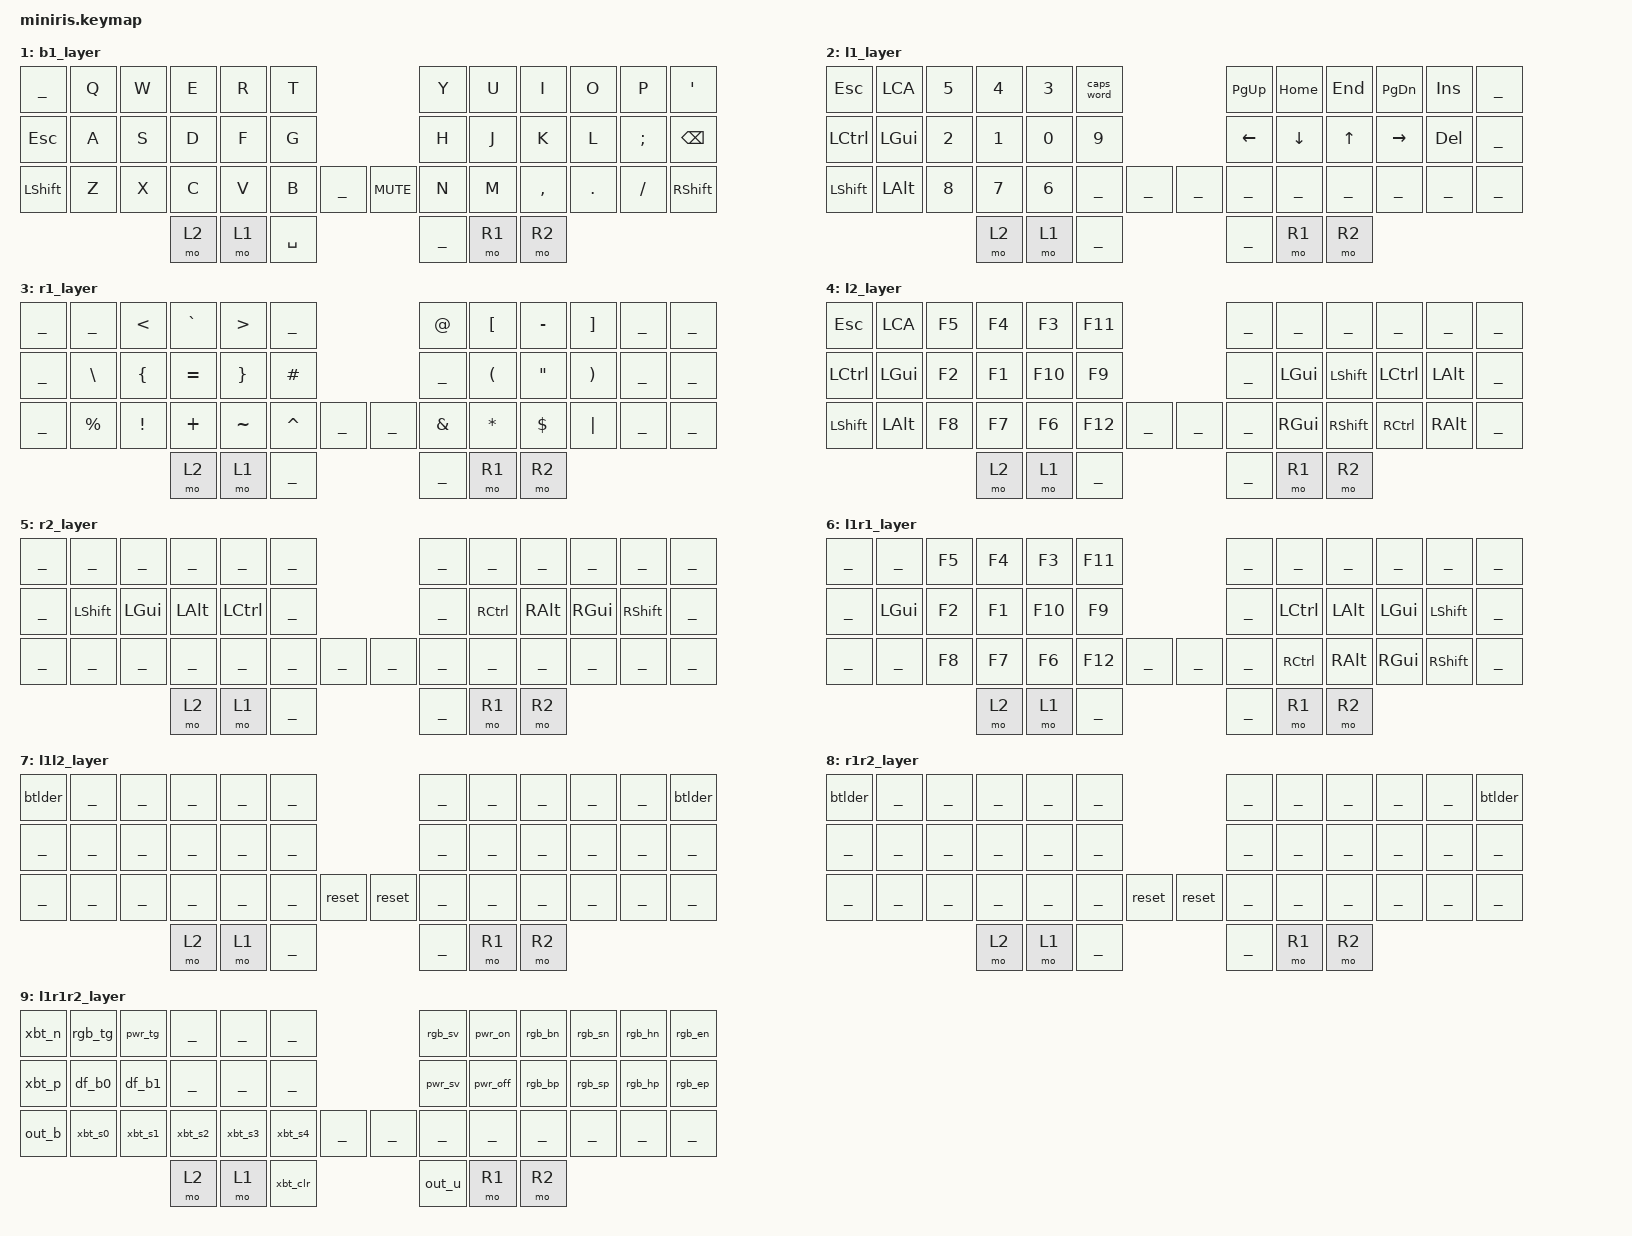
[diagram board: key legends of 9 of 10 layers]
#include <behaviors.dtsi>
#include <dt-bindings/zmk/keys.h>

#include "include/rgb_underglow.h"
#include "include/layers.dtsi"
#include "include/outputs.h"
#include "include/power.dtsi"
#include "include/power_rgb_underglow.dtsi"

#include "include/behaviors_ht.dtsi"
#include "include/miniris_homerow_mods.dtsi"
#include "include/keycodes.h"

/ {
keymap {
compatible = "zmk,keymap";
default_layer { bindings = <

  &kp TAB    &kp Q      &kp W      &kp E      LR1__ R    &kp T                         &kp Y      RR1__ U    &kp I      &kp O      &kp P      &kp SQT
  LC_ESC     LS__ A     LG__ S     LA__ D     LC__ F     LL1__ G                       RL1__ H    RC__ J     RA__ K     RG__ L     RS__ SEMI  RC_BSPC
  &kp LSHFT  &kp Z      &kp X      &kp C      LL1__ V    &kp B      ______ &kp C_MUTE  &kp N      RL1__ M    &kp COMMA  &kp DOT    &kp FSLH   &kp RSHFT
                                   &mo L2     &mo L1     &kp SPACE                     &kp RET    &mo R1     &mo R2                                         >;sensor-bindings = <
                                                                                                                                                            &inc_dec_kp N0 N1 &inc_dec_kp C_VOL_DN C_VOL_UP
                                                                                                                                                            >; };b1_layer { bindings = <
  ______     &kp Q      &kp W      &kp E      &kp R      &kp T                         &kp Y      &kp U      &kp I      &kp O      &kp P      &kp SQT
  &kp ESC    &kp A      &kp S      &kp D      &kp F      &kp G                         &kp H      &kp J      &kp K      &kp L      &kp SEMI   &kp BSPC
  &kp LSHFT  &kp Z      &kp X      &kp C      &kp V      &kp B      ______ &kp C_MUTE  &kp N      &kp M      &kp COMMA  &kp DOT    &kp FSLH   &kp RSHFT
                                   &mo L2     &mo L1     &kp SPACE                     ______     &mo R1     &mo R2                                         >;sensor-bindings = <
                                                                                                                                                            &inc_dec_kp N0 N1 &inc_dec_kp C_VOL_DN C_VOL_UP
                                                                                                                                                            >; };l1_layer { bindings = <
  &kp ESC    LCA        &kp N5     &kp N4     &kp N3     &caps_word                    &kp PG_UP  &kp HOME   &kp END    &kp PG_DN  &kp INS    ______
  &kp LCTRL  &kp LGUI   &kp N2     &kp N1     &kp N0     &kp N9                        &kp LEFT   &kp DOWN   &kp UP     &kp RIGHT  &kp DEL    ______
  &kp LSHIFT &kp LALT   &kp N8     &kp N7     &kp N6     ______     ______ ______      ______     ______     ______     ______     ______     ______
                                   &mo L2     &mo L1     ______                        ______     &mo R1     &mo R2                                         >;sensor-bindings = <
                                                                                                                                                            &inc_dec_kp N0 N1 &inc_dec_kp PG_UP PG_DN
                                                                                                                                                            >; };r1_layer { bindings = <
  ______     ______     &kp LT     &kp GRAVE  &kp GT     ______                        &kp AT     &kp LBKT   &kp MINUS  &kp RBKT   ______     ______
  ______     &kp BSLH   &kp LBRC   &kp EQUAL  &kp RBRC   &kp HASH                      &kp UNDER  &kp LPAR   &kp DQT    &kp RPAR   ______     ______
  ______     &kp PRCNT  &kp EXCL   &kp PLUS   &kp TILDE  &kp CARET  ______ ______      &kp AMPS   &kp STAR   &kp DLLR   &kp PIPE   ______     ______
                                   &mo L2     &mo L1     ______                        ______     &mo R1     &mo R2                                         >;sensor-bindings = <
                                                                                                                                                            &inc_dec_kp N0 N1 &inc_dec_kp PG_UP PG_DN
                                                                                                                                                            >; };l2_layer { bindings = <
  &kp ESC    LCA        &kp F5     &kp F4     &kp F3     &kp F11                       ______     ______     ______     ______     ______     ______
  &kp LCTRL  &kp LGUI   &kp F2     &kp F1     &kp F10    &kp F9                        ______     &kp LGUI   &kp LSHFT  &kp LCTRL  &kp LALT   ______
  &kp LSHIFT &kp LALT   &kp F8     &kp F7     &kp F6     &kp F12    ______ ______      ______     &kp RGUI   &kp RSHFT  &kp RCTRL  &kp RALT   ______
                                   &mo L2     &mo L1     ______                        ______     &mo R1     &mo R2                                         >;sensor-bindings = <
                                                                                                                                                            &inc_dec_kp N0 N1 &inc_dec_kp PG_UP PG_DN
                                                                                                                                                            >; };r2_layer { bindings = <
  ______     ______     ______     ______     ______     ______                        ______     ______     ______     ______     ______     ______
  ______     &kp LSHFT  &kp LGUI   &kp LALT   &kp LCTRL  ______                        ______     &kp RCTRL  &kp RALT   &kp RGUI   &kp RSHFT  ______
  ______     ______     ______     ______     ______     ______     ______ ______      ______     ______     ______     ______     ______     ______
                                   &mo L2     &mo L1     ______                        ______     &mo R1     &mo R2                                         >;sensor-bindings = <
                                                                                                                                                            &inc_dec_kp N0 N1 &inc_dec_kp PG_UP PG_DN
                                                                                                                                                            >; };l1r1_layer { bindings = <
  ______     ______     &kp F5     &kp F4     &kp F3     &kp F11                       ______     ______     ______     ______     ______     ______
  ______     &kp LGUI   &kp F2     &kp F1     &kp F10    &kp F9                        ______     &kp LCTRL  &kp LALT   &kp LGUI   &kp LSHFT  ______
  ______     ______     &kp F8     &kp F7     &kp F6     &kp F12    ______ ______      ______     &kp RCTRL  &kp RALT   &kp RGUI   &kp RSHFT  ______
                                   &mo L2     &mo L1     ______                        ______     &mo R1     &mo R2                                         >;sensor-bindings = <
                                                                                                                                                            &inc_dec_kp N0 N1 &inc_dec_kp PG_UP PG_DN
                                                                                                                                                            >; };l1l2_layer { bindings = <
  btlder     ______     ______     ______     ______     ______                        ______     ______     ______     ______     ______     btlder
  ______     ______     ______     ______     ______     ______                        ______     ______     ______     ______     ______     ______
  ______     ______     ______     ______     ______     ______     &reset &reset      ______     ______     ______     ______     ______     ______
                                   &mo L2     &mo L1     ______                        ______     &mo R1     &mo R2                                         >;sensor-bindings = <
                                                                                                                                                            &inc_dec_kp N0 N1 &inc_dec_kp PG_UP PG_DN
                                                                                                                                                            >; };r1r2_layer { bindings = <
  btlder     ______     ______     ______     ______     ______                        ______     ______     ______     ______     ______     btlder
  ______     ______     ______     ______     ______     ______                        ______     ______     ______     ______     ______     ______
  ______     ______     ______     ______     ______     ______     &reset &reset      ______     ______     ______     ______     ______     ______
                                   &mo L2     &mo L1     ______                        ______     &mo R1     &mo R2                                         >;sensor-bindings = <
                                                                                                                                                            &inc_dec_kp N0 N1 &inc_dec_kp PG_UP PG_DN
                                                                                                                                                            >; };l1r1r2_layer { bindings = <
  xbt_n      rgb_tg     pwr_tg     ______     ______     ______                        rgb_sv     pwr_on     rgb_bn     rgb_sn     rgb_hn     rgb_en
  xbt_p      df_b0      df_b1      ______     ______     ______                        pwr_sv     pwr_off    rgb_bp     rgb_sp     rgb_hp     rgb_ep
  out_b      xbt_s0     xbt_s1     xbt_s2     xbt_s3     xbt_s4     ______ ______      ______     ______     ______     ______     ______     ______
                                   &mo L2     &mo L1     xbt_clr                       out_u      &mo R1     &mo R2                                         >;sensor-bindings = <
                                                                                                                                                            &inc_dec_kp N0 N1 &inc_dec_kp PG_UP PG_DN
                                                                                                                                                            >; };
    };
};
